VERSION ""

NS_ :

BS_:

BU_: CCU Immobilizer
VAL_TABLE_ InhibitorUnlockState 3 "Others" 2 "Inhibit" 1 "Release" 0 "Default" ;
VAL_TABLE_ KeyPermissionState 3 "Others" 2 "Inhibit" 1 "Release" 0 "Default" ;

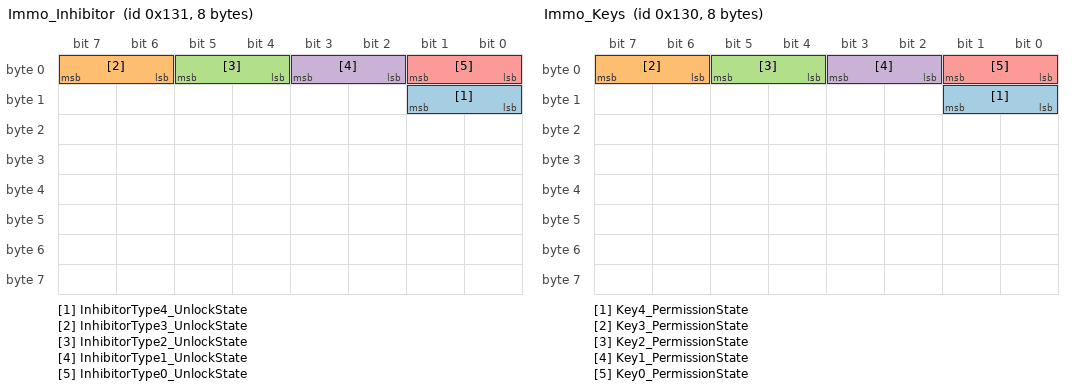
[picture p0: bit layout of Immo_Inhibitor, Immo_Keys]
BO_ 305 Immo_Inhibitor: 8 CCU
 SG_ InhibitorType4_UnlockState : 8|2@1+ (1,0) [0|0] ""  Immobilizer
 SG_ InhibitorType3_UnlockState : 6|2@1+ (1,0) [0|0] ""  Immobilizer
 SG_ InhibitorType2_UnlockState : 4|2@1+ (1,0) [0|0] ""  Immobilizer
 SG_ InhibitorType1_UnlockState : 2|2@1+ (1,0) [0|0] ""  Immobilizer
 SG_ InhibitorType0_UnlockState : 0|2@1+ (1,0) [0|0] ""  Immobilizer

BO_ 304 Immo_Keys: 8 Immobilizer
 SG_ Key4_PermissionState : 8|2@1+ (1,0) [0|0] ""  CCU
 SG_ Key3_PermissionState : 6|2@1+ (1,0) [0|0] ""  CCU
 SG_ Key2_PermissionState : 4|2@1+ (1,0) [0|0] ""  CCU
 SG_ Key1_PermissionState : 2|2@1+ (1,0) [0|0] ""  CCU
 SG_ Key0_PermissionState : 0|2@1+ (1,0) [0|0] ""  CCU

BA_DEF_  "BusType" STRING ;
BA_DEF_DEF_  "BusType" "CAN";
VAL_ 305 InhibitorType4_UnlockState 3 "Others" 2 "Inhibit" 1 "Release" 0 "Default" ;
VAL_ 305 InhibitorType3_UnlockState 3 "Others" 2 "Inhibit" 1 "Release" 0 "Default" ;
VAL_ 305 InhibitorType2_UnlockState 3 "Others" 2 "Inhibit" 1 "Release" 0 "Default" ;
VAL_ 305 InhibitorType1_UnlockState 3 "Others" 2 "Inhibit" 1 "Release" 0 "Default" ;
VAL_ 305 InhibitorType0_UnlockState 3 "Others" 2 "Inhibit" 1 "Release" 0 "Default" ;
VAL_ 304 Key4_PermissionState 3 "Others" 2 "Inhibit" 1 "Release" 0 "Default" ;
VAL_ 304 Key3_PermissionState 3 "Others" 2 "Inhibit" 1 "Release" 0 "Default" ;
VAL_ 304 Key2_PermissionState 3 "Others" 2 "Inhibit" 1 "Release" 0 "Default" ;
VAL_ 304 Key1_PermissionState 3 "Others" 2 "Inhibit" 1 "Release" 0 "Default" ;
VAL_ 304 Key0_PermissionState 3 "Others" 2 "Inhibit" 1 "Release" 0 "Default" ;
